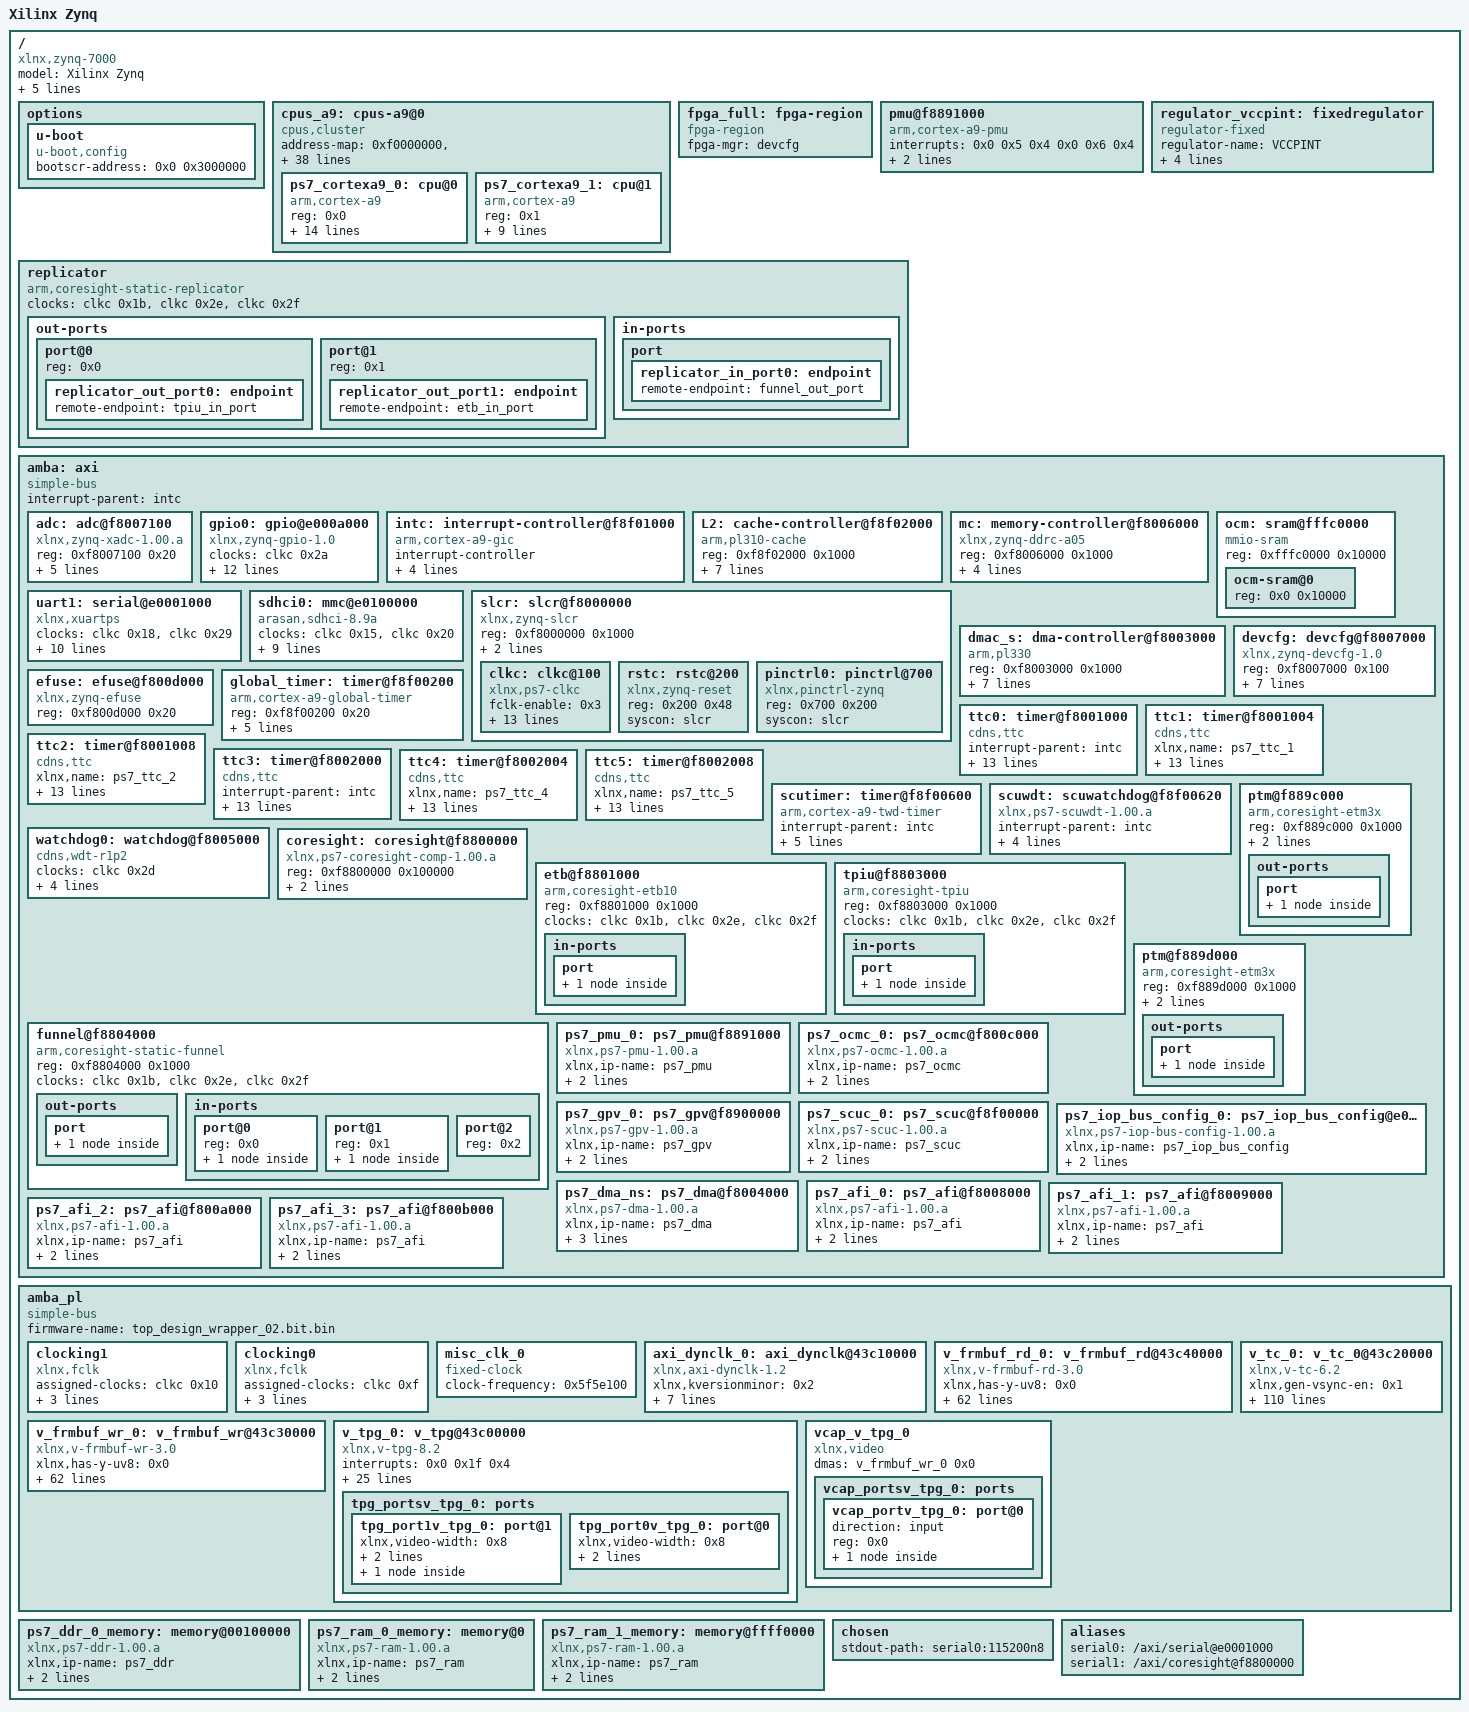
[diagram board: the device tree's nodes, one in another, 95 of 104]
/dts-v1/;
/ {
        #address-cells = <0x1>;
        #size-cells = <0x1>;
        compatible = "xlnx,zynq-7000";
        model = "Xilinx Zynq";
        device_id = "7z020";
        slrcount = <0x1>;
        family = "Zynq";
        speed_grade = "2";
        pruned-sdt = <0x1>;

        options {

                u-boot {
                        compatible = "u-boot,config";
                        bootscr-address = <0x0 0x3000000>;
                };
        };

        cpus_a9: cpus-a9@0 {
                phandle = <0x35>;
                #address-cells = <0x1>;
                #size-cells = <0x0>;
                compatible = "cpus,cluster";
                address-map = <0xf0000000 &amba 0xf0000000 0x10000000>,
                 <0x100000 &ps7_ddr_0_memory 0x100000 0x1ff00000>,
                 <0x0 &ps7_ram_0_memory 0x0 0x30000>,
                 <0xffff0000 &ps7_ram_1_memory 0xffff0000 0xfe00>,
                 <0x43c00000 &v_tpg_0 0x43c00000 0x10000>,
                 <0x43c10000 &axi_dynclk_0 0x43c10000 0x10000>,
                 <0x43c20000 &v_tc_0 0x43c20000 0x10000>,
                 <0x43c30000 &v_frmbuf_wr_0 0x43c30000 0x10000>,
                 <0x43c40000 &v_frmbuf_rd_0 0x43c40000 0x10000>,
                 <0xf8008000 &ps7_afi_0 0xf8008000 0x1000>,
                 <0xf8009000 &ps7_afi_1 0xf8009000 0x1000>,
                 <0xf800a000 &ps7_afi_2 0xf800a000 0x1000>,
                 <0xf800b000 &ps7_afi_3 0xf800b000 0x1000>,
                 <0xf8800000 &coresight 0xf8800000 0x100000>,
                 <0xf8006000 &mc 0xf8006000 0x1000>,
                 <0xf8007000 &devcfg 0xf8007000 0x100>,
                 <0xf8004000 &ps7_dma_ns 0xf8004000 0x1000>,
                 <0xf8003000 &dmac_s 0xf8003000 0x1000>,
                 <0xf8f00200 &global_timer 0xf8f00200 0x100>,
                 <0xe000a000 &gpio0 0xe000a000 0x1000>,
                 <0xf8900000 &ps7_gpv_0 0xf8900000 0x100000>,
                 <0xf8f01000 &intc 0xf8f01000 0x1000>,
                 <0xe0200000 &ps7_iop_bus_config_0 0xe0200000 0x1000>,
                 <0xf8f02000 &L2 0xf8f02000 0x1000>,
                 <0xf800c000 &ps7_ocmc_0 0xf800c000 0x1000>,
                 <0xf8891000 &ps7_pmu_0 0xf8891000 0x1000>,
                 <0xf8f00000 &ps7_scuc_0 0xf8f00000 0xfd>,
                 <0xf8f00600 &scutimer 0xf8f00600 0x20>,
                 <0xf8f00620 &scuwdt 0xf8f00620 0xe0>,
                 <0xe0100000 &sdhci0 0xe0100000 0x1000>,
                 <0xf8000000 &slcr 0xf8000000 0x1000>,
                 <0xf8001000 &ttc0 0xf8001000 0x1000>,
                 <0xf8002000 &ttc3 0xf8002000 0x1000>,
                 <0xe0001000 &uart1 0xe0001000 0x1000>,
                 <0xf8007100 &adc 0xf8007100 0x21>;
                #ranges-address-cells = <0x1>;
                #ranges-size-cells = <0x1>;

                ps7_cortexa9_0: cpu@0 {
                        phandle = <0x2e>;
                        compatible = "arm,cortex-a9";
                        device_type = "cpu";
                        reg = <0x0>;
                        clocks = <&clkc 0x3>;
                        clock-latency = <0x3e8>;
                        cpu0-supply = <&regulator_vccpint>;
                        operating-points = <0xa2c2b 0xf4240 0x51616 0xf4240>;
                        xlnx,i-cache-size = <0x8000>;
                        xlnx,d-cache-line-size = <0x14>;
                        xlnx,i-cache-line-size = <0x14>;
                        xlnx,cpu-1x-clk-freq-hz = <0x69f6bcb>;
                        xlnx,ip-name = "ps7_cortexa9";
                        xlnx,d-cache-size = <0x8000>;
                        xlnx,num-cores = <0x2>;
                        xlnx,cpu-clk-freq-hz = <0x27bc86bf>;
                        bus-handle = <0x1>;
                };

                ps7_cortexa9_1: cpu@1 {
                        phandle = <0x30>;
                        compatible = "arm,cortex-a9";
                        device_type = "cpu";
                        reg = <0x1>;
                        clocks = <&clkc 0x3>;
                        xlnx,i-cache-size = <0x8000>;
                        xlnx,d-cache-line-size = <0x14>;
                        xlnx,i-cache-line-size = <0x14>;
                        xlnx,cpu-1x-clk-freq-hz = <0x69f6bcb>;
                        xlnx,ip-name = "ps7_cortexa9";
                        xlnx,d-cache-size = <0x8000>;
                        xlnx,cpu-clk-freq-hz = <0x27bc86bf>;
                        bus-handle = <0x1>;
                };
        };

        fpga_full: fpga-region {
                phandle = <0x36>;
                compatible = "fpga-region";
                fpga-mgr = <&devcfg>;
                #address-cells = <0x1>;
                #size-cells = <0x1>;
                ranges;
        };

        pmu@f8891000 {
                compatible = "arm,cortex-a9-pmu";
                interrupts = <0x0 0x5 0x4 0x0 0x6 0x4>;
                interrupt-parent = <&intc>;
                reg = <0xf8891000 0x1000 0xf8893000 0x1000>;
        };

        regulator_vccpint: fixedregulator {
                phandle = <0x25>;
                compatible = "regulator-fixed";
                regulator-name = "VCCPINT";
                regulator-min-microvolt = <0xf4240>;
                regulator-max-microvolt = <0xf4240>;
                regulator-boot-on;
                regulator-always-on;
        };

        replicator {
                compatible = "arm,coresight-static-replicator";
                clocks = <&clkc 0x1b>,
                 <&clkc 0x2e>,
                 <&clkc 0x2f>;
                clock-names = "apb_pclk", "dbg_trc", "dbg_apb";

                out-ports {
                        #address-cells = <0x1>;
                        #size-cells = <0x0>;

                        port@0 {
                                reg = <0x0>;

                                replicator_out_port0: endpoint {
                                        phandle = <0x2a>;
                                        remote-endpoint = <&tpiu_in_port>;
                                };
                        };

                        port@1 {
                                reg = <0x1>;

                                replicator_out_port1: endpoint {
                                        phandle = <0x29>;
                                        remote-endpoint = <&etb_in_port>;
                                };
                        };
                };

                in-ports {

                        port {

                                replicator_in_port0: endpoint {
                                        phandle = <0x2b>;
                                        remote-endpoint = <&funnel_out_port>;
                                };
                        };
                };
        };

        amba: axi {
                phandle = <0x1>;
                bootph-all;
                compatible = "simple-bus";
                #address-cells = <0x1>;
                #size-cells = <0x1>;
                interrupt-parent = <&intc>;
                ranges;

                adc: adc@f8007100 {
                        phandle = <0x23>;
                        compatible = "xlnx,zynq-xadc-1.00.a";
                        reg = <0xf8007100 0x20>;
                        interrupts = <0x0 0x7 0x4>;
                        interrupt-parent = <&intc>;
                        clocks = <&clkc 0xc>;
                        status = "okay";
                        xlnx,ip-name = "ps7_xadc";
                        xlnx,name = "ps7_xadc_0";
                };

                gpio0: gpio@e000a000 {
                        phandle = <0x14>;
                        compatible = "xlnx,zynq-gpio-1.0";
                        #gpio-cells = <0x2>;
                        clocks = <&clkc 0x2a>;
                        gpio-controller;
                        interrupt-controller;
                        #interrupt-cells = <0x2>;
                        interrupt-parent = <&intc>;
                        interrupts = <0x0 0x14 0x4>;
                        reg = <0xe000a000 0x1000>;
                        xlnx,mio-gpio-mask = <0x5600>;
                        status = "okay";
                        gpio-mask-high = <0x0>;
                        xlnx,emio-gpio-width = <0x20>;
                        xlnx,ip-name = "ps7_gpio";
                        gpio-mask-low = <0x5600>;
                        emio-gpio-width = <0x20>;
                        xlnx,name = "ps7_gpio_0";
                };

                intc: interrupt-controller@f8f01000 {
                        phandle = <0x16>;
                        compatible = "arm,cortex-a9-gic";
                        #interrupt-cells = <0x3>;
                        interrupt-controller;
                        reg = <0xf8f01000 0x1000 0xf8f00100 0x100>;
                        status = "okay";
                        xlnx,irq-f2p-mode = "DIRECT";
                        xlnx,ip-name = "ps7_intc_dist";
                        xlnx,name = "ps7_intc_dist_0";
                };

                L2: cache-controller@f8f02000 {
                        phandle = <0x18>;
                        compatible = "arm,pl310-cache";
                        reg = <0xf8f02000 0x1000>;
                        interrupts = <0x0 0x2 0x4>;
                        arm,data-latency = <0x3 0x2 0x2>;
                        arm,tag-latency = <0x2 0x2 0x2>;
                        cache-unified;
                        cache-level = <0x2>;
                        status = "okay";
                        xlnx,ip-name = "ps7_pl310";
                        xlnx,name = "ps7_pl310_0";
                };

                mc: memory-controller@f8006000 {
                        phandle = <0xf>;
                        compatible = "xlnx,zynq-ddrc-a05";
                        reg = <0xf8006000 0x1000>;
                        status = "okay";
                        xlnx,ddr-clk-freq-hz = <0x1fca057e>;
                        xlnx,ip-name = "ps7_ddrc";
                        xlnx,has-ecc = <0x0>;
                        xlnx,name = "ps7_ddrc_0";
                };

                ocm: sram@fffc0000 {
                        phandle = <0x3b>;
                        compatible = "mmio-sram";
                        reg = <0xfffc0000 0x10000>;
                        #address-cells = <0x1>;
                        #size-cells = <0x1>;
                        ranges = <0x0 0xfffc0000 0x10000>;

                        ocm-sram@0 {
                                reg = <0x0 0x10000>;
                        };
                };

                uart1: serial@e0001000 {
                        phandle = <0x22>;
                        compatible = "xlnx,xuartps", "cdns,uart-r1p8";
                        status = "okay";
                        clocks = <&clkc 0x18>,
                         <&clkc 0x29>;
                        clock-names = "uart_clk", "pclk";
                        reg = <0xe0001000 0x1000>;
                        interrupts = <0x0 0x32 0x4>;
                        interrupt-parent = <&intc>;
                        xlnx,clock-freq = <0x5f5e100>;
                        xlnx,has-modem = <0x0>;
                        xlnx,ip-name = "ps7_uart";
                        cts-override;
                        port-number = <0x0>;
                        xlnx,uart-clk-freq-hz = <0x5f5e100>;
                        xlnx,name = "ps7_uart_1";
                };

                sdhci0: mmc@e0100000 {
                        phandle = <0x1e>;
                        compatible = "arasan,sdhci-8.9a";
                        status = "okay";
                        clock-names = "clk_xin", "clk_ahb";
                        clocks = <&clkc 0x15>,
                         <&clkc 0x20>;
                        interrupt-parent = <&intc>;
                        interrupts = <0x0 0x18 0x4>;
                        reg = <0xe0100000 0x1000>;
                        xlnx,has-power = <0x0>;
                        xlnx,ip-name = "ps7_sdio";
                        xlnx,sdio-clk-freq-hz = <0x5f5e100>;
                        xlnx,has-wp = <0x0>;
                        xlnx,has-cd = <0x0>;
                        xlnx,name = "ps7_sd_0";
                };

                slcr: slcr@f8000000 {
                        phandle = <0x1f>;
                        bootph-all;
                        #address-cells = <0x1>;
                        #size-cells = <0x1>;
                        compatible = "xlnx,zynq-slcr", "syscon", "simple-mfd";
                        reg = <0xf8000000 0x1000>;
                        ranges;
                        status = "okay";
                        xlnx,ip-name = "ps7_slcr";
                        xlnx,name = "ps7_slcr_0";

                        clkc: clkc@100 {
                                phandle = <0x24>;
                                bootph-all;
                                #clock-cells = <0x1>;
                                compatible = "xlnx,ps7-clkc";
                                fclk-enable = <0x3>;
                                clock-output-names = "armpll", "ddrpll", "iopll", "cpu_6or4x", "cpu_3or2x", "cpu_2x", "cpu_1x", "ddr2x", "ddr3x", "dci", "lqspi", "smc", "pcap", "gem0", "gem1", "fclk0", "fclk1", "fclk2", "fclk3", "can0", "can1", "sdio0", "sdio1", "uart0", "uart1", "spi0", "spi1", "dma", "usb0_aper", "usb1_aper", "gem0_aper", "gem1_aper", "sdio0_aper", "sdio1_aper", "spi0_aper", "spi1_aper", "can0_aper", "can1_aper", "i2c0_aper", "i2c1_aper", "uart0_aper", "uart1_aper", "gpio_aper", "lqspi_aper", "smc_aper", "swdt", "dbg_trc", "dbg_apb";
                                reg = <0x100 0x100>;
                                ps-clk-frequency = <0x1fca055>;
                        };

                        rstc: rstc@200 {
                                phandle = <0x46>;
                                compatible = "xlnx,zynq-reset";
                                reg = <0x200 0x48>;
                                #reset-cells = <0x1>;
                                syscon = <&slcr>;
                        };

                        pinctrl0: pinctrl@700 {
                                phandle = <0x47>;
                                compatible = "xlnx,pinctrl-zynq";
                                reg = <0x700 0x200>;
                                syscon = <&slcr>;
                        };
                };

                dmac_s: dma-controller@f8003000 {
                        phandle = <0x12>;
                        compatible = "arm,pl330", "arm,primecell";
                        reg = <0xf8003000 0x1000>;
                        interrupt-parent = <&intc>;
                        interrupts = <0x0 0xd 0x4 0x0 0xe 0x4 0x0 0xf 0x4 0x0 0x10 0x4 0x0 0x11 0x4 0x0 0x28 0x4 0x0 0x29 0x4 0x0 0x2a 0x4 0x0 0x2b 0x4>;
                        #dma-cells = <0x1>;
                        clocks = <&clkc 0x1b>;
                        clock-names = "apb_pclk";
                        status = "okay";
                        xlnx,ip-name = "ps7_dma";
                        xlnx,is-secure;
                        xlnx,name = "ps7_dma_s";
                };

                devcfg: devcfg@f8007000 {
                        phandle = <0x10>;
                        compatible = "xlnx,zynq-devcfg-1.0";
                        reg = <0xf8007000 0x100>;
                        interrupt-parent = <&intc>;
                        interrupts = <0x0 0x8 0x4>;
                        clocks = <&clkc 0xc>,
                         <&clkc 0xf>,
                         <&clkc 0x10>,
                         <&clkc 0x11>,
                         <&clkc 0x12>;
                        clock-names = "ref_clk", "fclk0", "fclk1", "fclk2", "fclk3";
                        syscon = <&slcr>;
                        status = "okay";
                        xlnx,ip-name = "ps7_dev_cfg";
                        xlnx,name = "ps7_dev_cfg_0";
                };

                efuse: efuse@f800d000 {
                        phandle = <0x48>;
                        compatible = "xlnx,zynq-efuse";
                        reg = <0xf800d000 0x20>;
                };

                global_timer: timer@f8f00200 {
                        phandle = <0x13>;
                        compatible = "arm,cortex-a9-global-timer";
                        reg = <0xf8f00200 0x20>;
                        interrupts = <0x1 0xb 0x301>;
                        interrupt-parent = <&intc>;
                        clocks = <&clkc 0x4>;
                        status = "okay";
                        xlnx,ip-name = "ps7_globaltimer";
                        xlnx,name = "ps7_globaltimer_0";
                };

                ttc0: timer@f8001000 {
                        phandle = <0x20>;
                        interrupt-parent = <&intc>;
                        interrupts = <0x0 0xa 0x4 0x0 0xb 0x4 0x0 0xc 0x4>;
                        compatible = "cdns,ttc";
                        clocks = <&clkc 0x6>;
                        reg = <0xf8001000 0x1000>;
                        xlnx,ttc-clk2-freq-hz = <0x69f6bcb>;
                        xlnx,ttc-clk1-clksrc = <0x0>;
                        status = "okay";
                        xlnx,clock-freq = <0x69f6bcb>;
                        xlnx,ttc-clk2-clksrc = <0x0>;
                        xlnx,ip-name = "ps7_ttc";
                        xlnx,ttc-clk0-freq-hz = <0x69f6bcb>;
                        xlnx,ttc-clk1-freq-hz = <0x69f6bcb>;
                        xlnx,ttc-clk0-clksrc = <0x0>;
                        xlnx,name = "ps7_ttc_0";
                };

                ttc1: timer@f8001004 {
                        phandle = <0x5a>;
                        xlnx,name = "ps7_ttc_1";
                        xlnx,ttc-clk0-clksrc = <0x0>;
                        xlnx,ttc-clk1-freq-hz = <0x69f6bcb>;
                        xlnx,ttc-clk0-freq-hz = <0x69f6bcb>;
                        xlnx,ip-name = "ps7_ttc";
                        xlnx,ttc-clk2-clksrc = <0x0>;
                        xlnx,clock-freq = <0x69f6bcb>;
                        status = "okay";
                        xlnx,ttc-clk1-clksrc = <0x0>;
                        xlnx,ttc-clk2-freq-hz = <0x69f6bcb>;
                        reg = <0xf8001004 0xffc>;
                        clocks = <&clkc 0x6>;
                        compatible = "cdns,ttc";
                        interrupts = <0x0 0xb 0x4 0x0 0xc 0x4>;
                        interrupt-parent = <&intc>;
                        lop-dynamic-ttc-node = <0x1>;
                };

                ttc2: timer@f8001008 {
                        phandle = <0x5b>;
                        xlnx,name = "ps7_ttc_2";
                        xlnx,ttc-clk0-clksrc = <0x0>;
                        xlnx,ttc-clk1-freq-hz = <0x69f6bcb>;
                        xlnx,ttc-clk0-freq-hz = <0x69f6bcb>;
                        xlnx,ip-name = "ps7_ttc";
                        xlnx,ttc-clk2-clksrc = <0x0>;
                        xlnx,clock-freq = <0x69f6bcb>;
                        status = "okay";
                        xlnx,ttc-clk1-clksrc = <0x0>;
                        xlnx,ttc-clk2-freq-hz = <0x69f6bcb>;
                        reg = <0xf8001008 0xff8>;
                        clocks = <&clkc 0x6>;
                        compatible = "cdns,ttc";
                        interrupts = <0x0 0xc 0x4>;
                        interrupt-parent = <&intc>;
                        lop-dynamic-ttc-node = <0x1>;
                };

                ttc3: timer@f8002000 {
                        phandle = <0x21>;
                        interrupt-parent = <&intc>;
                        interrupts = <0x0 0x25 0x4 0x0 0x26 0x4 0x0 0x27 0x4>;
                        compatible = "cdns,ttc";
                        clocks = <&clkc 0x6>;
                        reg = <0xf8002000 0x1000>;
                        xlnx,ttc-clk2-freq-hz = <0x69f6bcb>;
                        xlnx,ttc-clk1-clksrc = <0x0>;
                        status = "okay";
                        xlnx,clock-freq = <0x69f6bcb>;
                        xlnx,ttc-clk2-clksrc = <0x0>;
                        xlnx,ip-name = "ps7_ttc";
                        xlnx,ttc-clk0-freq-hz = <0x69f6bcb>;
                        xlnx,ttc-clk1-freq-hz = <0x69f6bcb>;
                        xlnx,ttc-clk0-clksrc = <0x0>;
                        xlnx,name = "ps7_ttc_3";
                };

                ttc4: timer@f8002004 {
                        phandle = <0x5c>;
                        xlnx,name = "ps7_ttc_4";
                        xlnx,ttc-clk0-clksrc = <0x0>;
                        xlnx,ttc-clk1-freq-hz = <0x69f6bcb>;
                        xlnx,ttc-clk0-freq-hz = <0x69f6bcb>;
                        xlnx,ip-name = "ps7_ttc";
                        xlnx,ttc-clk2-clksrc = <0x0>;
                        xlnx,clock-freq = <0x69f6bcb>;
                        status = "okay";
                        xlnx,ttc-clk1-clksrc = <0x0>;
                        xlnx,ttc-clk2-freq-hz = <0x69f6bcb>;
                        reg = <0xf8002004 0xffc>;
                        clocks = <&clkc 0x6>;
                        compatible = "cdns,ttc";
                        interrupts = <0x0 0x26 0x4 0x0 0x27 0x4>;
                        interrupt-parent = <&intc>;
                        lop-dynamic-ttc-node = <0x1>;
                };

                ttc5: timer@f8002008 {
                        phandle = <0x5d>;
                        xlnx,name = "ps7_ttc_5";
                        xlnx,ttc-clk0-clksrc = <0x0>;
                        xlnx,ttc-clk1-freq-hz = <0x69f6bcb>;
                        xlnx,ttc-clk0-freq-hz = <0x69f6bcb>;
                        xlnx,ip-name = "ps7_ttc";
                        xlnx,ttc-clk2-clksrc = <0x0>;
                        xlnx,clock-freq = <0x69f6bcb>;
                        status = "okay";
                        xlnx,ttc-clk1-clksrc = <0x0>;
                        xlnx,ttc-clk2-freq-hz = <0x69f6bcb>;
                        reg = <0xf8002008 0xff8>;
                        clocks = <&clkc 0x6>;
                        compatible = "cdns,ttc";
                        interrupts = <0x0 0x27 0x4>;
                        interrupt-parent = <&intc>;
                        lop-dynamic-ttc-node = <0x1>;
                };

                scutimer: timer@f8f00600 {
                        phandle = <0x1c>;
                        bootph-all;
                        interrupt-parent = <&intc>;
                        interrupts = <0x1 0xd 0x301>;
                        compatible = "arm,cortex-a9-twd-timer";
                        reg = <0xf8f00600 0x20>;
                        clocks = <&clkc 0x4>;
                        status = "okay";
                        xlnx,ip-name = "ps7_scutimer";
                        xlnx,name = "ps7_scutimer_0";
                };

                scuwdt: scuwatchdog@f8f00620 {
                        phandle = <0x1d>;
                        interrupt-parent = <&intc>;
                        interrupts = <0x1 0xe 0x4>;
                        compatible = "xlnx,ps7-scuwdt-1.00.a";
                        reg = <0xf8f00620 0xe0>;
                        status = "okay";
                        xlnx,ip-name = "ps7_scuwdt";
                        xlnx,name = "ps7_scuwdt_0";
                };

                watchdog0: watchdog@f8005000 {
                        phandle = <0x4b>;
                        clocks = <&clkc 0x2d>;
                        compatible = "cdns,wdt-r1p2";
                        interrupt-parent = <&intc>;
                        interrupts = <0x0 0x9 0x1>;
                        reg = <0xf8005000 0x1000>;
                        timeout-sec = <0xa>;
                };

                coresight: coresight@f8800000 {
                        phandle = <0xe>;
                        compatible = "xlnx,ps7-coresight-comp-1.00.a";
                        status = "okay";
                        reg = <0xf8800000 0x100000>;
                        xlnx,ip-name = "ps7_coresight_comp";
                        xlnx,name = "ps7_coresight_comp_0";
                };

                etb@f8801000 {
                        compatible = "arm,coresight-etb10", "arm,primecell";
                        reg = <0xf8801000 0x1000>;
                        clocks = <&clkc 0x1b>,
                         <&clkc 0x2e>,
                         <&clkc 0x2f>;
                        clock-names = "apb_pclk", "dbg_trc", "dbg_apb";

                        in-ports {

                                port {

                                        etb_in_port: endpoint {
                                                phandle = <0x27>;
                                                remote-endpoint = <&replicator_out_port1>;
                                        };
                                };
                        };
                };

                tpiu@f8803000 {
                        compatible = "arm,coresight-tpiu", "arm,primecell";
                        reg = <0xf8803000 0x1000>;
                        clocks = <&clkc 0x1b>,
                         <&clkc 0x2e>,
                         <&clkc 0x2f>;
                        clock-names = "apb_pclk", "dbg_trc", "dbg_apb";

                        in-ports {

                                port {

                                        tpiu_in_port: endpoint {
                                                phandle = <0x26>;
                                                remote-endpoint = <&replicator_out_port0>;
                                        };
                                };
                        };
                };

                funnel@f8804000 {
                        compatible = "arm,coresight-static-funnel", "arm,primecell";
                        reg = <0xf8804000 0x1000>;
                        clocks = <&clkc 0x1b>,
                         <&clkc 0x2e>,
                         <&clkc 0x2f>;
                        clock-names = "apb_pclk", "dbg_trc", "dbg_apb";

                        out-ports {

                                port {

                                        funnel_out_port: endpoint {
                                                phandle = <0x28>;
                                                remote-endpoint = <&replicator_in_port0>;
                                        };
                                };
                        };

                        in-ports {
                                #address-cells = <0x1>;
                                #size-cells = <0x0>;

                                port@0 {
                                        reg = <0x0>;

                                        funnel0_in_port0: endpoint {
                                                phandle = <0x2f>;
                                                remote-endpoint = <&ptm0_out_port>;
                                        };
                                };

                                port@1 {
                                        reg = <0x1>;

                                        funnel0_in_port1: endpoint {
                                                phandle = <0x31>;
                                                remote-endpoint = <&ptm1_out_port>;
                                        };
                                };

                                port@2 {
                                        reg = <0x2>;
                                };
                        };
                };

                ptm@f889c000 {
                        compatible = "arm,coresight-etm3x", "arm,primecell";
                        reg = <0xf889c000 0x1000>;
                        clocks = <&clkc 0x1b>,
                         <&clkc 0x2e>,
                         <&clkc 0x2f>;
                        clock-names = "apb_pclk", "dbg_trc", "dbg_apb";
                        cpu = <&ps7_cortexa9_0>;

                        out-ports {

                                port {

                                        ptm0_out_port: endpoint {
                                                phandle = <0x2c>;
                                                remote-endpoint = <&funnel0_in_port0>;
                                        };
                                };
                        };
                };

                ptm@f889d000 {
                        compatible = "arm,coresight-etm3x", "arm,primecell";
                        reg = <0xf889d000 0x1000>;
                        clocks = <&clkc 0x1b>,
                         <&clkc 0x2e>,
                         <&clkc 0x2f>;
                        clock-names = "apb_pclk", "dbg_trc", "dbg_apb";
                        cpu = <&ps7_cortexa9_1>;

                        out-ports {

                                port {

                                        ptm1_out_port: endpoint {
                                                phandle = <0x2d>;
                                                remote-endpoint = <&funnel0_in_port1>;
                                        };
                                };
                        };
                };

                ps7_pmu_0: ps7_pmu@f8891000 {
                        phandle = <0x1a>;
                        compatible = "xlnx,ps7-pmu-1.00.a";
                        status = "okay";
                        xlnx,ip-name = "ps7_pmu";
                        reg = <0xf8891000 0x1000 0xf8893000 0x1000>;
                        xlnx,name = "ps7_pmu_0";
                };

                ps7_ocmc_0: ps7_ocmc@f800c000 {
                        phandle = <0x19>;
                        compatible = "xlnx,ps7-ocmc-1.00.a";
                        status = "okay";
                        xlnx,ip-name = "ps7_ocmc";
                        reg = <0xf800c000 0x1000>;
                        xlnx,name = "ps7_ocmc_0";
                };

                ps7_gpv_0: ps7_gpv@f8900000 {
                        phandle = <0x15>;
                        compatible = "xlnx,ps7-gpv-1.00.a";
                        status = "okay";
                        xlnx,ip-name = "ps7_gpv";
                        reg = <0xf8900000 0x100000>;
                        xlnx,name = "ps7_gpv_0";
                };

                ps7_scuc_0: ps7_scuc@f8f00000 {
                        phandle = <0x1b>;
                        compatible = "xlnx,ps7-scuc-1.00.a";
                        status = "okay";
                        xlnx,ip-name = "ps7_scuc";
                        reg = <0xf8f00000 0xfd>;
                        xlnx,name = "ps7_scuc_0";
                };

                ps7_iop_bus_config_0: ps7_iop_bus_config@e0200000 {
                        phandle = <0x17>;
                        compatible = "xlnx,ps7-iop-bus-config-1.00.a";
                        status = "okay";
                        xlnx,ip-name = "ps7_iop_bus_config";
                        reg = <0xe0200000 0x1000>;
                        xlnx,name = "ps7_iop_bus_config_0";
                };

                ps7_dma_ns: ps7_dma@f8004000 {
                        phandle = <0x11>;
                        compatible = "xlnx,ps7-dma-1.00.a";
                        status = "okay";
                        xlnx,ip-name = "ps7_dma";
                        xlnx,is-secure;
                        reg = <0xf8004000 0x1000>;
                        xlnx,name = "ps7_dma_ns";
                };

                ps7_afi_0: ps7_afi@f8008000 {
                        phandle = <0xa>;
                        compatible = "xlnx,ps7-afi-1.00.a";
                        status = "okay";
                        xlnx,ip-name = "ps7_afi";
                        reg = <0xf8008000 0x1000>;
                        xlnx,name = "ps7_afi_0";
                };

                ps7_afi_1: ps7_afi@f8009000 {
                        phandle = <0xb>;
                        compatible = "xlnx,ps7-afi-1.00.a";
                        status = "okay";
                        xlnx,ip-name = "ps7_afi";
                        reg = <0xf8009000 0x1000>;
                        xlnx,name = "ps7_afi_1";
                };

                ps7_afi_2: ps7_afi@f800a000 {
                        phandle = <0xc>;
                        compatible = "xlnx,ps7-afi-1.00.a";
                        status = "okay";
                        xlnx,ip-name = "ps7_afi";
                        reg = <0xf800a000 0x1000>;
                        xlnx,name = "ps7_afi_2";
                };

                ps7_afi_3: ps7_afi@f800b000 {
                        phandle = <0xd>;
                        compatible = "xlnx,ps7-afi-1.00.a";
                        status = "okay";
                        xlnx,ip-name = "ps7_afi";
                        reg = <0xf800b000 0x1000>;
                        xlnx,name = "ps7_afi_3";
                };
        };

        amba_pl: amba_pl {
                phandle = <0x51>;
                ranges;
                compatible = "simple-bus";
                #address-cells = <0x1>;
                #size-cells = <0x1>;
                firmware-name = "top_design_wrapper_02.bit.bin";

                clocking1: clocking1 {
                        phandle = <0x52>;
                        compatible = "xlnx,fclk";
                        assigned-clocks = <&clkc 0x10>;
                        assigned-clock-rates = <0x8d9ee20>;
                        #clock-cells = <0x0>;
                        clock-output-names = "fabric_clk";
                        clocks = <&clkc 0x10>;
                };

                clocking0: clocking0 {
                        phandle = <0x53>;
                        compatible = "xlnx,fclk";
                        assigned-clocks = <&clkc 0xf>;
                        assigned-clock-rates = <0x5f5e100>;
                        #clock-cells = <0x0>;
                        clock-output-names = "fabric_clk";
                        clocks = <&clkc 0xf>;
                };

                misc_clk_0: misc_clk_0 {
                        phandle = <0x32>;
                        compatible = "fixed-clock";
                        clock-frequency = <0x5f5e100>;
                        #clock-cells = <0x0>;
                };

                axi_dynclk_0: axi_dynclk@43c10000 {
                        phandle = <0x6>;
                        xlnx,kversionminor = <0x2>;
                        xlnx,kversionmajor = <0x1>;
                        xlnx,krefclkfreqhz = <0x5f5e100>;
                        compatible = "xlnx,axi-dynclk-1.2";
                        status = "okay";
                        clock-names = "REF_CLK_I", "s_axi_lite_aclk";
                        xlnx,ip-name = "axi_dynclk";
                        xlnx,edk-iptype = "PERIPHERAL";
                        reg = <0x43c10000 0x10000>;
                        clocks = <&clkc 0xf>,
                         <&clkc 0xf>;
                        xlnx,name = "axi_dynclk_0";
                };

                v_frmbuf_rd_0: v_frmbuf_rd@43c40000 {
                        phandle = <0x9>;
                        xlnx,has-y-uv8 = <0x0>;
                        xlnx,max-height = <0x438>;
                        xlnx,has-bgra8 = <0x0>;
                        xlnx,has-rgba8 = <0x0>;
                        xlnx,ip-name = "v_frmbuf_rd";
                        reg = <0x43c40000 0x10000>;
                        xlnx,s-axi-ctrl-addr-width = <0x7>;
                        xlnx,pixels-per-clock = <0x1>;
                        xlnx,samples-per-clock = <0x1>;
                        xlnx,max-nr-planes = <0x1>;
                        xlnx,has-bgr8 = <0x0>;
                        xlnx,has-rgb8 = <0x1>;
                        xlnx,has-y-uv8-420 = <0x0>;
                        xlnx,has-yuyv8 = <0x0>;
                        xlnx,has-y-u-v8 = <0x0>;
                        interrupt-names = "interrupt";
                        compatible = "xlnx,v-frmbuf-rd-3.0", "xlnx,axi-frmbuf-rd-v2.2";
                        xlnx,max-width = <0x780>;
                        xlnx,has-rgb16 = <0x0>;
                        xlnx,vid-formats = "bgr888";
                        xlnx,has-bgrx8 = <0x0>;
                        xlnx,has-rgbx8 = <0x0>;
                        xlnx,has-rgbx10 = <0x0>;
                        interrupt-parent = <&intc>;
                        xlnx,aximm-num-outstanding = <0x4>;
                        xlnx,has-uyvy8 = <0x0>;
                        xlnx,use-uram = <0x0>;
                        xlnx,has-rgbx12 = <0x0>;
                        xlnx,aximm-burst-length = <0x10>;
                        xlnx,aximm-addr-width = <0x20>;
                        xlnx,video-width = <0x8>;
                        xlnx,max-cols = <0x780>;
                        xlnx,has-yuv8 = <0x0>;
                        status = "okay";
                        xlnx,has-y-uv10-420 = <0x0>;
                        xlnx,has-yuva8 = <0x0>;
                        xlnx,has-y-uv12-420 = <0x0>;
                        xlnx,name = "v_frmbuf_rd_0";
                        interrupts = <0x0 0x1e 0x4>;
                        xlnx,has-y10 = <0x0>;
                        xlnx,has-y-uv16-420 = <0x0>;
                        xlnx,has-y12 = <0x0>;
                        xlnx,has-alpha = <0x0>;
                        xlnx,has-y-u-v10 = <0x0>;
                        clocks = <&clkc 0x10>;
                        xlnx,has-y16 = <0x0>;
                        xlnx,dma-align = <0x8>;
                        xlnx,has-y-u-v12 = <0x0>;
                        xlnx,edk-iptype = "PERIPHERAL";
                        xlnx,has-interlaced = <0x0>;
                        xlnx,has-yuv16 = <0x0>;
                        xlnx,has-yuvx8 = <0x0>;
                        xlnx,is-tile-format = <0x0>;
                        xlnx,dma-addr-width = <0x20>;
                        clock-names = "ap_clk";
                        xlnx,s-axi-ctrl-data-width = <0x20>;
                        xlnx,has-y8 = <0x0>;
                        xlnx,has-y-uv10 = <0x0>;
                        xlnx,has-y-uv12 = <0x0>;
                        xlnx,max-rows = <0x438>;
                        xlnx,has-yuvx10 = <0x0>;
                        #dma-cells = <0x1>;
                        xlnx,has-yuvx12 = <0x0>;
                        xlnx,has-y-uv16 = <0x0>;
                        xlnx,max-data-width = <0x8>;
                        xlnx,has-y-u-v8-420 = <0x0>;
                        xlnx,num-video-components = <0x3>;
                        xlnx,aximm-data-width = <0x40>;
                };

                v_frmbuf_wr_0: v_frmbuf_wr@43c30000 {
                        phandle = <0x8>;
                        xlnx,has-y-uv8 = <0x0>;
                        xlnx,max-height = <0x438>;
                        xlnx,has-bgra8 = <0x0>;
                        xlnx,has-rgba8 = <0x0>;
                        xlnx,ip-name = "v_frmbuf_wr";
                        reg = <0x43c30000 0x10000>;
                        xlnx,s-axi-ctrl-addr-width = <0x7>;
                        xlnx,pixels-per-clock = <0x1>;
                        xlnx,samples-per-clock = <0x1>;
                        xlnx,max-nr-planes = <0x1>;
                        xlnx,has-bgr8 = <0x0>;
                        xlnx,has-rgb8 = <0x1>;
                        xlnx,has-y-uv8-420 = <0x0>;
                        xlnx,has-yuyv8 = <0x0>;
                        xlnx,has-y-u-v8 = <0x0>;
                        interrupt-names = "interrupt";
                        compatible = "xlnx,v-frmbuf-wr-3.0", "xlnx,axi-frmbuf-wr-v2.2";
                        xlnx,max-width = <0x780>;
                        xlnx,has-rgb16 = <0x0>;
                        xlnx,vid-formats = "bgr888";
                        xlnx,has-bgrx8 = <0x0>;
                        xlnx,has-rgbx8 = <0x0>;
                        xlnx,has-rgbx10 = <0x0>;
                        interrupt-parent = <&intc>;
                        xlnx,aximm-num-outstanding = <0x4>;
                        xlnx,has-uyvy8 = <0x0>;
                        xlnx,use-uram = <0x0>;
                        xlnx,has-rgbx12 = <0x0>;
                        xlnx,aximm-burst-length = <0x10>;
                        xlnx,aximm-addr-width = <0x20>;
                        xlnx,video-width = <0x8>;
                        xlnx,max-cols = <0x780>;
                        xlnx,has-yuv8 = <0x0>;
                        status = "okay";
                        xlnx,has-y-uv10-420 = <0x0>;
                        xlnx,has-yuva8 = <0x0>;
                        xlnx,has-y-uv12-420 = <0x0>;
                        xlnx,name = "v_frmbuf_wr_0";
                        interrupts = <0x0 0x1d 0x4>;
                        xlnx,has-y10 = <0x0>;
                        xlnx,has-y-uv16-420 = <0x0>;
                        xlnx,has-y12 = <0x0>;
                        xlnx,has-alpha = <0x0>;
                        xlnx,has-y-u-v10 = <0x0>;
                        clocks = <&clkc 0x10>;
                        xlnx,has-y16 = <0x0>;
                        xlnx,dma-align = <0x8>;
                        xlnx,has-y-u-v12 = <0x0>;
                        xlnx,edk-iptype = "PERIPHERAL";
                        xlnx,has-interlaced = <0x0>;
                        xlnx,has-yuv16 = <0x0>;
                        xlnx,has-yuvx8 = <0x0>;
                        xlnx,is-tile-format = <0x0>;
                        xlnx,dma-addr-width = <0x20>;
                        clock-names = "ap_clk";
                        xlnx,s-axi-ctrl-data-width = <0x20>;
                        xlnx,has-y8 = <0x0>;
                        xlnx,has-y-uv10 = <0x0>;
                        xlnx,has-y-uv12 = <0x0>;
                        xlnx,max-rows = <0x438>;
                        xlnx,has-yuvx10 = <0x0>;
                        #dma-cells = <0x1>;
                        xlnx,has-yuvx12 = <0x0>;
                        xlnx,has-y-uv16 = <0x0>;
                        xlnx,max-data-width = <0x8>;
                        xlnx,has-y-u-v8-420 = <0x0>;
                        xlnx,num-video-components = <0x3>;
                        xlnx,aximm-data-width = <0x40>;
                };

                v_tc_0: v_tc_0@43c20000 {
                        phandle = <0x7>;
                        xlnx,gen-vsync-en = <0x1>;
                        xlnx,gen-hframe-size = <0x898>;
                        xlnx,num-fsyncs = <0x1>;
                        xlnx,gen-hactive-size = <0x780>;
                        xlnx,gen-video-format = <0x2>;
                        xlnx,gen-f1-vblank-hstart = <0x7d8>;
                        xlnx,active-video-detection;
                        xlnx,horizontal-sync-generation;
                        xlnx,gen-vblank-en = <0x1>;
                        xlnx,gen-avideo-en = <0x1>;
                        xlnx,ip-name = "v_tc";
                        xlnx,fsync-hstart10 = <0x0>;
                        xlnx,max-pixels = <0x1000>;
                        xlnx,gen-fieldid-en = <0x0>;
                        reg = <0x43c20000 0x10000>;
                        xlnx,det-vblank-en = <0x1>;
                        xlnx,fsync-hstart11 = <0x0>;
                        xlnx,fsync-hstart12 = <0x0>;
                        xlnx,pixels-per-clock = <0x4>;
                        xlnx,gen-interlaced = <0x0>;
                        xlnx,det-avideo-en = <0x1>;
                        xlnx,fsync-hstart13 = <0x0>;
                        xlnx,fsync-hstart14 = <0x0>;
                        xlnx,gen-f0-vblank-hend = <0x7d8>;
                        xlnx,fsync-hstart15 = <0x0>;
                        xlnx,det-hsync-en = <0x1>;
                        interrupt-names = "irq";
                        xlnx,enable-generation;
                        xlnx,gen-avideo-polarity = <0x1>;
                        xlnx,max-lines-per-frame = <0x1000>;
                        xlnx,has-axi4-lite = <0x1>;
                        compatible = "xlnx,v-tc-6.2", "xlnx,bridge-v-tc-6.1";
                        xlnx,max-clocks-per-line = <0x1000>;
                        xlnx,gen-f0-vframe-size = <0x465>;
                        xlnx,gen-f0-vblank-hstart = <0x7d8>;
                        interrupt-parent = <&intc>;
                        xlnx,max-lines = <0x1000>;
                        xlnx,gen-f0-vsync-vstart = <0x43b>;
                        xlnx,horizontal-blank-generation;
                        xlnx,gen-hsync-end = <0x804>;
                        xlnx,gen-f0-vsync-hstart = <0x7d8>;
                        xlnx,gen-f1-vsync-hend = <0x7d8>;
                        xlnx,vertical-blank-detection;
                        xlnx,gen-vsync-polarity = <0x1>;
                        xlnx,fsync-vstart0 = <0x0>;
                        xlnx,gen-hsync-polarity = <0x1>;
                        xlnx,fsync-vstart1 = <0x0>;
                        status = "okay";
                        xlnx,fsync-vstart2 = <0x0>;
                        xlnx,gen-hsync-start = <0x7d8>;
                        xlnx,gen-f0-vsync-vend = <0x440>;
                        xlnx,fsync-vstart3 = <0x0>;
                        xlnx,vertical-sync-detection;
                        xlnx,frame-syncs = <0x1>;
                        xlnx,fsync-vstart4 = <0x0>;
                        xlnx,gen-vactive-size = <0x438>;
                        xlnx,name = "v_tc_0";
                        xlnx,fsync-vstart5 = <0x0>;
                        interrupts = <0x0 0x20 0x4>;
                        xlnx,gen-achroma-en = <0x0>;
                        xlnx,fsync-vstart6 = <0x0>;
                        xlnx,det-fieldid-en = <0x0>;
                        xlnx,fsync-vstart7 = <0x0>;
                        xlnx,gen-hsync-en = <0x1>;
                        xlnx,fsync-vstart8 = <0x0>;
                        xlnx,fsync-vstart10 = <0x0>;
                        xlnx,fsync-vstart9 = <0x0>;
                        xlnx,fsync-vstart11 = <0x0>;
                        xlnx,arbitrary-res-en = [00];
                        xlnx,fsync-vstart12 = <0x0>;
                        xlnx,fsync-vstart13 = <0x0>;
                        clocks = <&misc_clk_0>,
                         <&clkc 0xf>;
                        xlnx,fsync-vstart14 = <0x0>;
                        xlnx,fsync-vstart15 = <0x0>;
                        xlnx,gen-cparity = <0x0>;
                        xlnx,edk-iptype = "PERIPHERAL";
                        xlnx,vertical-sync-generation;
                        xlnx,gen-f1-vblank-hend = <0x7d8>;
                        xlnx,det-vsync-en = <0x1>;
                        xlnx,gen-vblank-polarity = <0x1>;
                        xlnx,fsync-hstart0 = <0x0>;
                        clock-names = "clk", "s_axi_aclk";
                        xlnx,interlace-en = <0x0>;
                        xlnx,gen-auto-switch = <0x0>;
                        xlnx,fsync-hstart1 = <0x0>;
                        xlnx,fsync-hstart2 = <0x0>;
                        xlnx,active-video-generation;
                        xlnx,fsync-hstart3 = <0x0>;
                        xlnx,fsync-hstart4 = <0x0>;
                        xlnx,horizontal-blank-detection;
                        xlnx,fsync-hstart5 = <0x0>;
                        xlnx,gen-f1-vframe-size = <0x465>;
                        xlnx,fsync-hstart6 = <0x0>;
                        xlnx,fsync-hstart7 = <0x0>;
                        xlnx,fsync-hstart8 = <0x0>;
                        xlnx,gen-hblank-en = <0x1>;
                        xlnx,fsync-hstart9 = <0x0>;
                        xlnx,horizontal-sync-detection;
                        xlnx,gen-f1-vsync-vend = <0x440>;
                        xlnx,detect-en = <0x0>;
                        xlnx,det-hblank-en = <0x1>;
                        xlnx,vid-ppc = <0x4>;
                        xlnx,has-intc-if = <0x0>;
                        xlnx,generate-en = <0x1>;
                        xlnx,gen-achroma-polarity = <0x1>;
                        xlnx,sync-en = <0x0>;
                        xlnx,det-achroma-en = <0x0>;
                        xlnx,generator;
                        xlnx,gen-f1-vsync-vstart = <0x43b>;
                        xlnx,vertical-blank-generation;
                        xlnx,gen-hblank-polarity = <0x1>;
                        xlnx,video-mode = "1080p";
                        xlnx,gen-fieldid-polarity = <0x1>;
                        xlnx,gen-f1-vsync-hstart = <0x7d8>;
                        xlnx,gen-f0-vsync-hend = <0x7d8>;
                };

                v_tpg_0: v_tpg@43c00000 {
                        phandle = <0x5>;
                        interrupts = <0x0 0x1f 0x4>;
                        compatible = "xlnx,v-tpg-8.2", "xlnx,v-tpg-8.0";
                        xlnx,max-width = <0x780>;
                        xlnx,foreground = <0x1>;
                        xlnx,max-height = <0x438>;
                        interrupt-parent = <&intc>;
                        xlnx,max-rows = <0x438>;
                        xlnx,solid-color = <0x1>;
                        xlnx,has-axi4-yuv422-yuv420 = <0x0>;
                        xlnx,ip-name = "v_tpg";
                        reg = <0x43c00000 0x10000>;
                        clocks = <&clkc 0x10>;
                        xlnx,color-bar = <0x1>;
                        xlnx,s-axi-ctrl-addr-width = <0x8>;
                        xlnx,samples-per-clock = <0x1>;
                        xlnx,max-data-width = <0x8>;
                        xlnx,has-axi4s-slave = <0x0>;
                        xlnx,ppc = <0x1>;
                        xlnx,max-cols = <0x780>;
                        xlnx,edk-iptype = "PERIPHERAL";
                        status = "okay";
                        clock-names = "ap_clk";
                        xlnx,zone-plate = <0x1>;
                        xlnx,num-video-components = <0x3>;
                        interrupt-names = "interrupt";
                        xlnx,ramp = <0x1>;
                        xlnx,color-sweep = <0x1>;
                        xlnx,s-axi-ctrl-data-width = <0x20>;
                        xlnx,display-port = <0x1>;
                        xlnx,name = "v_tpg_0";

                        tpg_portsv_tpg_0: ports {
                                phandle = <0x55>;
                                #address-cells = <0x1>;
                                #size-cells = <0x0>;

                                tpg_port1v_tpg_0: port@1 {
                                        phandle = <0x56>;
                                        xlnx,video-width = <0x8>;
                                        reg = <0x1>;
                                        xlnx,video-format = <0x2>;

                                        tpg_outv_tpg_0: endpoint {
                                                phandle = <0x34>;
                                                remote-endpoint = <&v_frmbuf_wr_0v_tpg_0>;
                                        };
                                };

                                tpg_port0v_tpg_0: port@0 {
                                        phandle = <0x57>;
                                        xlnx,video-width = <0x8>;
                                        reg = <0x0>;
                                        xlnx,video-format = <0x2>;
                                };
                        };
                };

                vcap_v_tpg_0 {
                        compatible = "xlnx,video";
                        dmas = <&v_frmbuf_wr_0 0x0>;
                        dma-names = "port0";

                        vcap_portsv_tpg_0: ports {
                                phandle = <0x58>;
                                #address-cells = <0x1>;
                                #size-cells = <0x0>;

                                vcap_portv_tpg_0: port@0 {
                                        phandle = <0x59>;
                                        direction = "input";
                                        reg = <0x0>;

                                        v_frmbuf_wr_0v_tpg_0: endpoint {
                                                phandle = <0x33>;
                                                remote-endpoint = <&tpg_outv_tpg_0>;
                                        };
                                };
                        };
                };
        };

        ps7_ddr_0_memory: memory@00100000 {
                phandle = <0x2>;
                compatible = "xlnx,ps7-ddr-1.00.a";
                xlnx,ip-name = "ps7_ddr";
                device_type = "memory";
                memory_type = "memory";
                reg = <0x100000 0x1ff00000>;
        };

        ps7_ram_0_memory: memory@0 {
                phandle = <0x3>;
                compatible = "xlnx,ps7-ram-1.00.a";
                xlnx,ip-name = "ps7_ram";
                device_type = "memory";
                memory_type = "memory";
                reg = <0x0 0x30000>;
        };

        ps7_ram_1_memory: memory@ffff0000 {
                phandle = <0x4>;
                compatible = "xlnx,ps7-ram-1.00.a";
                xlnx,ip-name = "ps7_ram";
                device_type = "memory";
                memory_type = "memory";
                reg = <0xffff0000 0xfe00>;
        };

        chosen {
                stdout-path = "serial0:115200n8";
        };

        aliases {
                serial0 = "/axi/serial@e0001000";
                serial1 = "/axi/coresight@f8800000";
        };

        __symbols__ {
                cpus_a9 = "/cpus-a9@0";
                ps7_cortexa9_0 = "/cpus-a9@0/cpu@0";
                ps7_cortexa9_1 = "/cpus-a9@0/cpu@1";
                fpga_full = "/fpga-region";
                regulator_vccpint = "/fixedregulator";
                replicator_out_port0 = "/replicator/out-ports/port@0/endpoint";
                replicator_out_port1 = "/replicator/out-ports/port@1/endpoint";
                replicator_in_port0 = "/replicator/in-ports/port/endpoint";
                amba = "/axi";
                adc = "/axi/adc@f8007100";
                gpio0 = "/axi/gpio@e000a000";
                intc = "/axi/interrupt-controller@f8f01000";
                L2 = "/axi/cache-controller@f8f02000";
                mc = "/axi/memory-controller@f8006000";
                ocm = "/axi/sram@fffc0000";
                uart1 = "/axi/serial@e0001000";
                sdhci0 = "/axi/mmc@e0100000";
                slcr = "/axi/slcr@f8000000";
                clkc = "/axi/slcr@f8000000/clkc@100";
                rstc = "/axi/slcr@f8000000/rstc@200";
                pinctrl0 = "/axi/slcr@f8000000/pinctrl@700";
                dmac_s = "/axi/dma-controller@f8003000";
                devcfg = "/axi/devcfg@f8007000";
                efuse = "/axi/efuse@f800d000";
                global_timer = "/axi/timer@f8f00200";
                scutimer = "/axi/timer@f8f00600";
                scuwdt = "/axi/scuwatchdog@f8f00620";
                watchdog0 = "/axi/watchdog@f8005000";
                coresight = "/axi/coresight@f8800000";
                etb_in_port = "/axi/etb@f8801000/in-ports/port/endpoint";
                tpiu_in_port = "/axi/tpiu@f8803000/in-ports/port/endpoint";
                funnel_out_port = "/axi/funnel@f8804000/out-ports/port/endpoint";
                funnel0_in_port0 = "/axi/funnel@f8804000/in-ports/port@0/endpoint";
                funnel0_in_port1 = "/axi/funnel@f8804000/in-ports/port@1/endpoint";
                ptm0_out_port = "/axi/ptm@f889c000/out-ports/port/endpoint";
                ptm1_out_port = "/axi/ptm@f889d000/out-ports/port/endpoint";
                ps7_pmu_0 = "/axi/ps7_pmu@f8891000";
                ps7_ocmc_0 = "/axi/ps7_ocmc@f800c000";
                ps7_gpv_0 = "/axi/ps7_gpv@f8900000";
                ps7_scuc_0 = "/axi/ps7_scuc@f8f00000";
                ps7_iop_bus_config_0 = "/axi/ps7_iop_bus_config@e0200000";
                ps7_dma_ns = "/axi/ps7_dma@f8004000";
                ps7_afi_0 = "/axi/ps7_afi@f8008000";
                ps7_afi_1 = "/axi/ps7_afi@f8009000";
                ps7_afi_2 = "/axi/ps7_afi@f800a000";
                ps7_afi_3 = "/axi/ps7_afi@f800b000";
                amba_pl = "/amba_pl";
                clocking1 = "/amba_pl/clocking1";
                clocking0 = "/amba_pl/clocking0";
                misc_clk_0 = "/amba_pl/misc_clk_0";
                axi_dynclk_0 = "/amba_pl/axi_dynclk@43c10000";
                v_frmbuf_rd_0 = "/amba_pl/v_frmbuf_rd@43c40000";
                v_frmbuf_wr_0 = "/amba_pl/v_frmbuf_wr@43c30000";
                v_tc_0 = "/amba_pl/v_tc_0@43c20000";
                v_tpg_0 = "/amba_pl/v_tpg@43c00000";
                tpg_portsv_tpg_0 = "/amba_pl/v_tpg@43c00000/ports";
                tpg_port1v_tpg_0 = "/amba_pl/v_tpg@43c00000/ports/port@1";
                tpg_outv_tpg_0 = "/amba_pl/v_tpg@43c00000/ports/port@1/endpoint";
                tpg_port0v_tpg_0 = "/amba_pl/v_tpg@43c00000/ports/port@0";
                vcap_portsv_tpg_0 = "/amba_pl/vcap_v_tpg_0/ports";
                vcap_portv_tpg_0 = "/amba_pl/vcap_v_tpg_0/ports/port@0";
                v_frmbuf_wr_0v_tpg_0 = "/amba_pl/vcap_v_tpg_0/ports/port@0/endpoint";
                ps7_ddr_0_memory = "/memory@00100000";
                ps7_ram_0_memory = "/memory@0";
                ps7_ram_1_memory = "/memory@ffff0000";
        };
};
